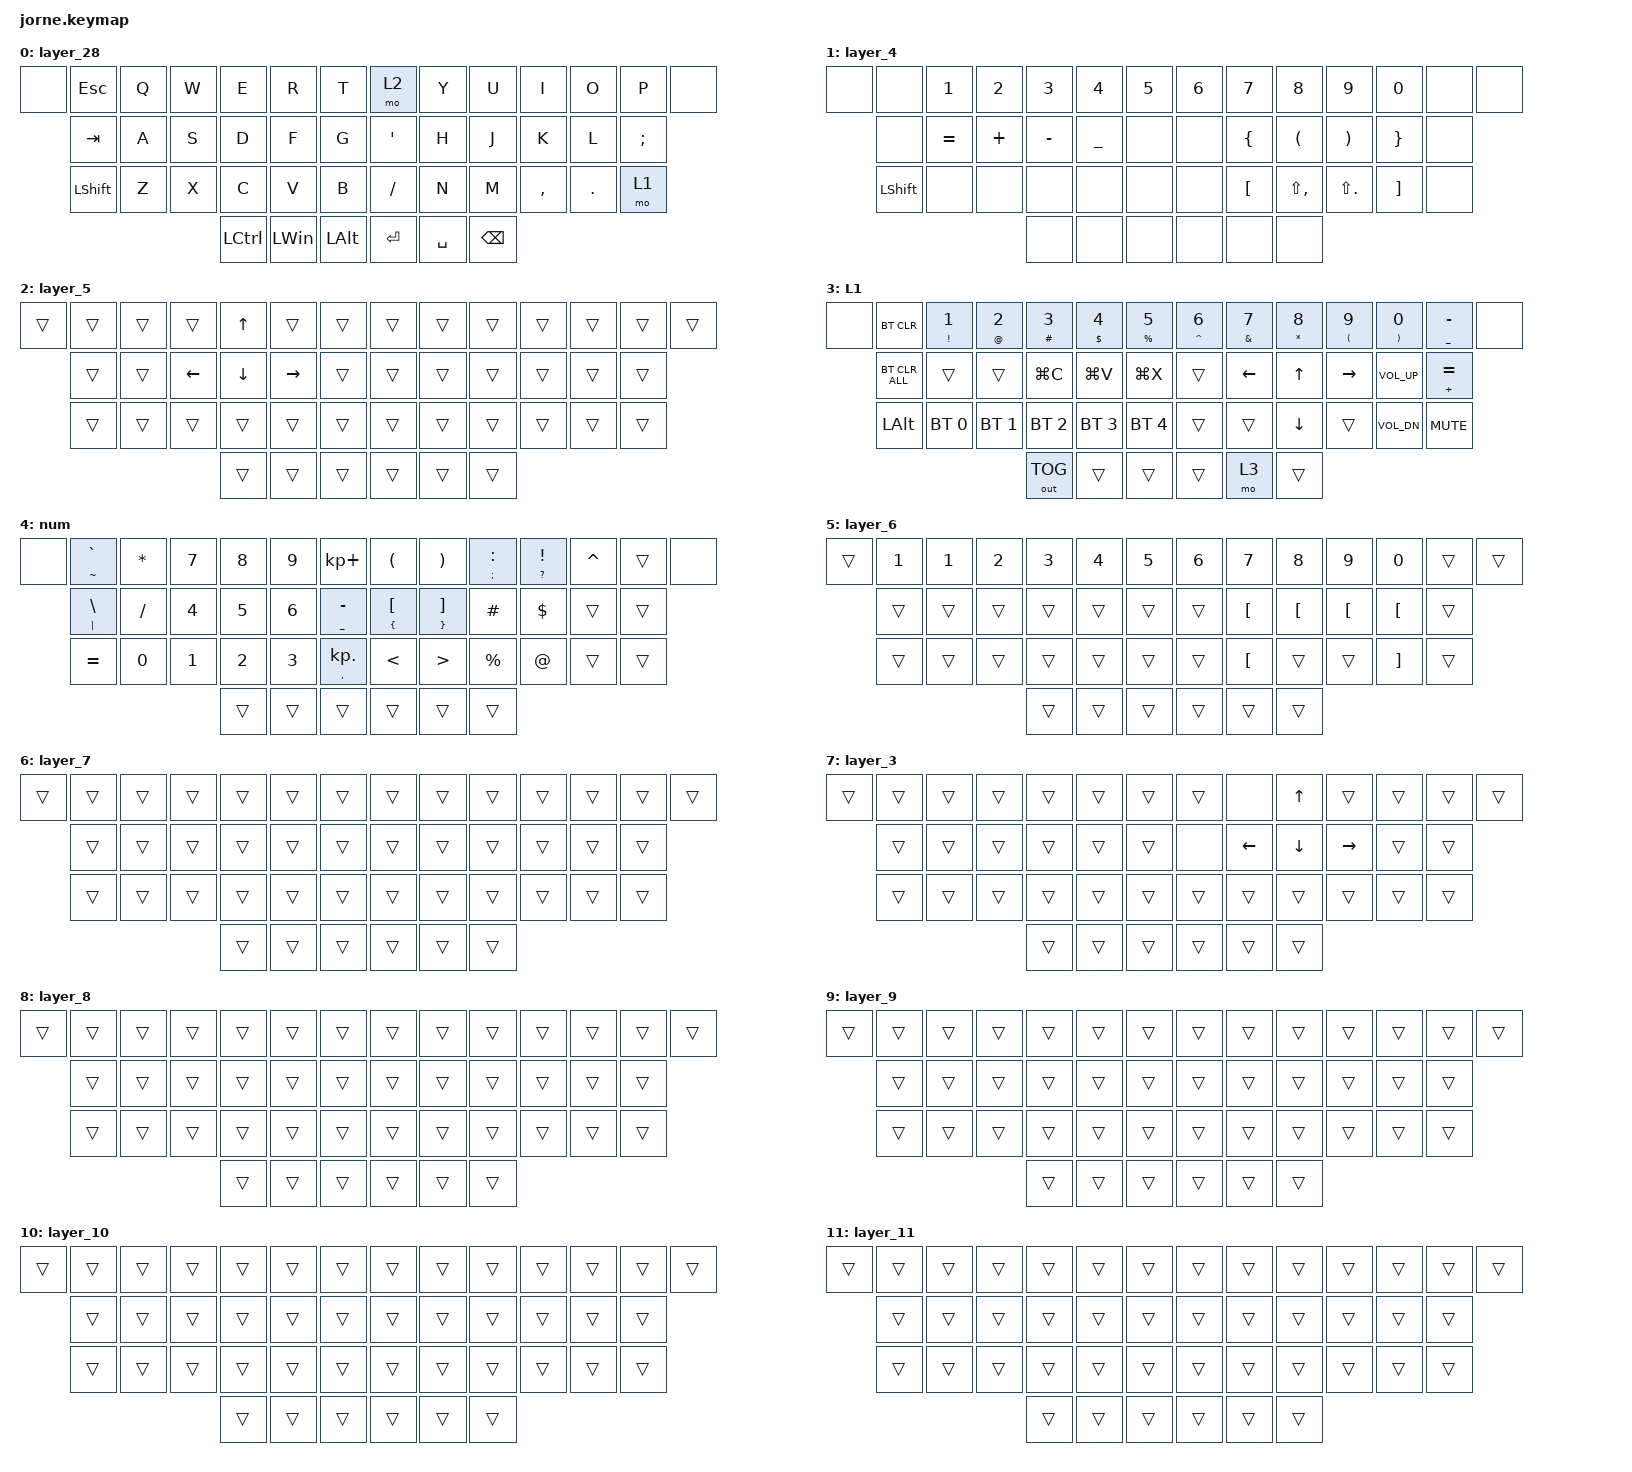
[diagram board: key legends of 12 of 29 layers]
/*
 * Copyright (c) 2020 The ZMK Contributors
 *
 * SPDX-License-Identifier: MIT
 */

#include <behaviors.dtsi>
#include <dt-bindings/zmk/bt.h>
#include <dt-bindings/zmk/keys.h>
#include <dt-bindings/zmk/outputs.h>

/ {
    combos {
        compatible = "zmk,combos";

        combo_game {
            bindings = <&tog 28>;
            key-positions = <38 43>;
            timeout-ms = <200>;
        };
    };

    behaviors {
        hml: hml {
            compatible = "zmk,behavior-hold-tap";
            label = "HML";
            bindings = <&kp>, <&kp>;

            #binding-cells = <2>;
            tapping-term-ms = <220>;
            quick-tap-ms = <175>;
            flavor = "balanced";
            require-prior-idle-ms = <100>;
            hold-trigger-key-positions = <7 8 9 10 11 12 13 20 21 22 23 24 25 32 33 34 35 36 37 38 39 40 41 42 43>;
            hold-trigger-on-release;
        };

        hmr: hmr {
            compatible = "zmk,behavior-hold-tap";
            label = "HMR";
            bindings = <&kp>, <&kp>;

            #binding-cells = <2>;
            tapping-term-ms = <220>;
            quick-tap-ms = <175>;
            require-prior-idle-ms = <100>;
            flavor = "balanced";
            hold-trigger-key-positions = <0 1 2 3 4 5 6 14 15 16 17 18 19 26 27 28 29 30 31 38 39 40 41 42 43>;
            hold-trigger-on-release;
        };

        tkl: tkl {
            compatible = "zmk,behavior-hold-tap";
            label = "TKL";
            bindings = <&mo>, <&kp>;

            #binding-cells = <2>;
            tapping-term-ms = <220>;
            quick-tap-ms = <175>;
            flavor = "balanced";
            require-prior-idle-ms = <100>;
            hold-trigger-key-positions = <7 8 9 10 11 12 13 20 21 22 23 24 25 32 33 34 35 36 37 38 39 40 41 42 43>;
            hold-trigger-on-release;
        };

        tkr: tkr {
            compatible = "zmk,behavior-hold-tap";
            label = "TKR";
            bindings = <&mo>, <&kp>;

            #binding-cells = <2>;
            tapping-term-ms = <220>;
            quick-tap-ms = <175>;
            require-prior-idle-ms = <100>;
            flavor = "balanced";
            hold-trigger-key-positions = <0 1 2 3 4 5 6 14 15 16 17 18 19 26 27 28 29 30 31 38 39 40 41 42 43>;
            hold-trigger-on-release;
        };
    };

    keymap {
        compatible = "zmk,keymap";

        layer_28 {
            bindings = <
&none  &kp ESC     &kp Q  &kp W  &kp E      &kp R     &kp T           &mo 2      &kp Y      &kp U          &kp I      &kp O    &kp P          &none
       &kp TAB     &kp A  &kp S  &kp D      &kp F     &kp G           &kp APOS   &kp H      &kp J          &kp K      &kp L    &kp SEMICOLON
       &kp LSHIFT  &kp Z  &kp X  &kp C      &kp V     &kp B           &kp SLASH  &kp N      &kp M          &kp COMMA  &kp DOT  &mo 1
                                 &kp LCTRL  &kp LWIN  &kp LEFT_ALT    &kp ENTER  &kp SPACE  &kp BACKSPACE
            >;
        };

        layer_4 {
            bindings = <
&none  &none           &kp NUMBER_1  &kp NUMBER_2  &kp NUMBER_3  &kp NUMBER_4    &kp NUMBER_5    &kp NUMBER_6  &kp NUMBER_7    &kp NUMBER_8          &kp NUMBER_9           &kp NUMBER_0     &none  &none
       &none           &kp EQUAL     &kp PLUS      &kp MINUS     &kp UNDERSCORE  &none           &none         &kp LEFT_BRACE  &kp LEFT_PARENTHESIS  &kp RIGHT_PARENTHESIS  &kp RIGHT_BRACE  &none
       &kp LEFT_SHIFT  &none         &none         &none         &none           &none           &none         &kp LBKT        &kp LS(COMMA)         &kp LS(DOT)            &kp RBKT         &none
                                                   &none         &none           &none           &none         &none           &none
            >;
        };

        layer_5 {
            bindings = <
&trans  &trans  &trans  &trans          &kp UP_ARROW    &trans     &trans    &trans  &trans  &trans  &trans  &trans  &trans  &trans
        &trans  &trans  &kp LEFT_ARROW  &kp DOWN_ARROW  &kp RIGHT  &trans    &trans  &trans  &trans  &trans  &trans  &trans
        &trans  &trans  &trans          &trans          &trans     &trans    &trans  &trans  &trans  &trans  &trans  &trans
                                        &trans          &trans     &trans    &trans  &trans  &trans
            >;
        };

        L1 {
            bindings = <
&none  &bt BT_CLR      &mt EXCLAMATION NUMBER_1  &mt AT_SIGN NUMBER_2  &mt POUND NUMBER_3  &mt DOLLAR NUMBER_4  &mt PERCENT NUMBER_5    &mt CARET NUMBER_6  &mt AMPERSAND NUMBER_7  &mt ASTERISK NUMBER_8  &mt LEFT_PARENTHESIS NUMBER_9  &mt RIGHT_PARENTHESIS NUMBER_0  &mt UNDERSCORE MINUS  &none
       &bt BT_CLR_ALL  &trans                    &trans                &kp LG(C)           &kp LG(V)            &kp LG(X)               &trans              &kp LEFT_ARROW          &kp UP_ARROW           &kp RIGHT_ARROW                &kp C_VOLUME_UP                 &mt PLUS EQUAL
       &kp LEFT_ALT    &bt BT_SEL 0              &bt BT_SEL 1          &bt BT_SEL 2        &bt BT_SEL 3         &bt BT_SEL 4            &trans              &trans                  &kp DOWN_ARROW         &trans                         &kp C_VOL_DN                    &kp K_MUTE
                                                                       &out OUT_TOG        &trans               &trans                  &trans              &mo 3                   &trans
            >;
        };

        num {
            bindings = <
&none  &mt TILDE GRAVE  &kp ASTERISK  &kp N7  &kp N8  &kp N9  &kp KP_PLUS             &kp LEFT_PARENTHESIS         &kp RIGHT_PARENTHESIS          &mt SEMICOLON COLON  &mt QUESTION EXCLAMATION  &kp CARET  &trans  &none
       &mt PIPE BSLH    &kp SLASH     &kp N4  &kp N5  &kp N6  &mt UNDERSCORE MINUS    &mt LEFT_BRACE LEFT_BRACKET  &mt RIGHT_BRACE RIGHT_BRACKET  &kp HASH             &kp DOLLAR                &trans     &trans
       &kp EQUAL        &kp NUMBER_0  &kp N1  &kp N2  &kp N3  &mt COMMA KP_DOT        &kp LESS_THAN                &kp GREATER_THAN               &kp PERCENT          &kp AT_SIGN               &trans     &trans
                                              &trans  &trans  &trans                  &trans                       &trans                         &trans
            >;
        };

        layer_6 {
            bindings = <
&trans  &kp N1  &kp N1  &kp N2  &kp N3  &kp N4  &kp N5    &kp N6  &kp N7    &kp N8    &kp N9    &kp N0    &trans  &trans
        &trans  &trans  &trans  &trans  &trans  &trans    &trans  &kp LBKT  &kp LBKT  &kp LBKT  &kp LBKT  &trans
        &trans  &trans  &trans  &trans  &trans  &trans    &trans  &kp LBKT  &trans    &trans    &kp RBKT  &trans
                                &trans  &trans  &trans    &trans  &trans    &trans
            >;
        };

        layer_7 {
            bindings = <
&trans  &trans  &trans  &trans  &trans  &trans  &trans    &trans  &trans  &trans  &trans  &trans  &trans  &trans
        &trans  &trans  &trans  &trans  &trans  &trans    &trans  &trans  &trans  &trans  &trans  &trans
        &trans  &trans  &trans  &trans  &trans  &trans    &trans  &trans  &trans  &trans  &trans  &trans
                                &trans  &trans  &trans    &trans  &trans  &trans
            >;
        };

        layer_3 {
            bindings = <
&trans  &trans  &trans  &trans  &trans  &trans  &trans    &trans  &none     &kp UP_ARROW    &trans     &trans  &trans  &trans
        &trans  &trans  &trans  &trans  &trans  &trans    &none   &kp LEFT  &kp DOWN_ARROW  &kp RIGHT  &trans  &trans
        &trans  &trans  &trans  &trans  &trans  &trans    &trans  &trans    &trans          &trans     &trans  &trans
                                &trans  &trans  &trans    &trans  &trans    &trans
            >;
        };

        layer_8 {
            bindings = <
&trans  &trans  &trans  &trans  &trans  &trans  &trans    &trans  &trans  &trans  &trans  &trans  &trans  &trans
        &trans  &trans  &trans  &trans  &trans  &trans    &trans  &trans  &trans  &trans  &trans  &trans
        &trans  &trans  &trans  &trans  &trans  &trans    &trans  &trans  &trans  &trans  &trans  &trans
                                &trans  &trans  &trans    &trans  &trans  &trans
            >;
        };

        layer_9 {
            bindings = <
&trans  &trans  &trans  &trans  &trans  &trans  &trans    &trans  &trans  &trans  &trans  &trans  &trans  &trans
        &trans  &trans  &trans  &trans  &trans  &trans    &trans  &trans  &trans  &trans  &trans  &trans
        &trans  &trans  &trans  &trans  &trans  &trans    &trans  &trans  &trans  &trans  &trans  &trans
                                &trans  &trans  &trans    &trans  &trans  &trans
            >;
        };

        layer_10 {
            bindings = <
&trans  &trans  &trans  &trans  &trans  &trans  &trans    &trans  &trans  &trans  &trans  &trans  &trans  &trans
        &trans  &trans  &trans  &trans  &trans  &trans    &trans  &trans  &trans  &trans  &trans  &trans
        &trans  &trans  &trans  &trans  &trans  &trans    &trans  &trans  &trans  &trans  &trans  &trans
                                &trans  &trans  &trans    &trans  &trans  &trans
            >;
        };

        layer_11 {
            bindings = <
&trans  &trans  &trans  &trans  &trans  &trans  &trans    &trans  &trans  &trans  &trans  &trans  &trans  &trans
        &trans  &trans  &trans  &trans  &trans  &trans    &trans  &trans  &trans  &trans  &trans  &trans
        &trans  &trans  &trans  &trans  &trans  &trans    &trans  &trans  &trans  &trans  &trans  &trans
                                &trans  &trans  &trans    &trans  &trans  &trans
            >;
        };

        layer_12 {
            bindings = <
&trans  &trans  &trans  &trans  &trans  &trans  &trans    &trans  &trans  &trans  &trans  &trans  &trans  &trans
        &trans  &trans  &trans  &trans  &trans  &trans    &trans  &trans  &trans  &trans  &trans  &trans
        &trans  &trans  &trans  &trans  &trans  &trans    &trans  &trans  &trans  &trans  &trans  &trans
                                &trans  &trans  &trans    &trans  &trans  &trans
            >;
        };

        layer_13 {
            bindings = <
&trans  &trans  &trans  &trans  &trans  &trans  &trans    &trans  &trans  &trans  &trans  &trans  &trans  &trans
        &trans  &trans  &trans  &trans  &trans  &trans    &trans  &trans  &trans  &trans  &trans  &trans
        &trans  &trans  &trans  &trans  &trans  &trans    &trans  &trans  &trans  &trans  &trans  &trans
                                &trans  &trans  &trans    &trans  &trans  &trans
            >;
        };

        layer_14 {
            bindings = <
&trans  &trans  &trans  &trans  &trans  &trans  &trans    &trans  &trans  &trans  &trans  &trans  &trans  &trans
        &trans  &trans  &trans  &trans  &trans  &trans    &trans  &trans  &trans  &trans  &trans  &trans
        &trans  &trans  &trans  &trans  &trans  &trans    &trans  &trans  &trans  &trans  &trans  &trans
                                &trans  &trans  &trans    &trans  &trans  &trans
            >;
        };

        layer_15 {
            bindings = <
&trans  &trans  &trans  &trans  &trans  &trans  &trans    &trans  &trans  &trans  &trans  &trans  &trans  &trans
        &trans  &trans  &trans  &trans  &trans  &trans    &trans  &trans  &trans  &trans  &trans  &trans
        &trans  &trans  &trans  &trans  &trans  &trans    &trans  &trans  &trans  &trans  &trans  &trans
                                &trans  &trans  &trans    &trans  &trans  &trans
            >;
        };

        layer_16 {
            bindings = <
&trans  &trans  &trans  &trans  &trans  &trans  &trans    &trans  &trans  &trans  &trans  &trans  &trans  &trans
        &trans  &trans  &trans  &trans  &trans  &trans    &trans  &trans  &trans  &trans  &trans  &trans
        &trans  &trans  &trans  &trans  &trans  &trans    &trans  &trans  &trans  &trans  &trans  &trans
                                &trans  &trans  &trans    &trans  &trans  &trans
            >;
        };

        layer_17 {
            bindings = <
&trans  &trans  &trans  &trans  &trans  &trans  &trans    &trans  &trans  &trans  &trans  &trans  &trans  &trans
        &trans  &trans  &trans  &trans  &trans  &trans    &trans  &trans  &trans  &trans  &trans  &trans
        &trans  &trans  &trans  &trans  &trans  &trans    &trans  &trans  &trans  &trans  &trans  &trans
                                &trans  &trans  &trans    &trans  &trans  &trans
            >;
        };

        layer_18 {
            bindings = <
&trans  &trans  &trans  &trans  &trans  &trans  &trans    &trans  &trans  &trans  &trans  &trans  &trans  &trans
        &trans  &trans  &trans  &trans  &trans  &trans    &trans  &trans  &trans  &trans  &trans  &trans
        &trans  &trans  &trans  &trans  &trans  &trans    &trans  &trans  &trans  &trans  &trans  &trans
                                &trans  &trans  &trans    &trans  &trans  &trans
            >;
        };

        layer_19 {
            bindings = <
&trans  &trans  &trans  &trans  &trans  &trans  &trans    &trans  &trans  &trans  &trans  &trans  &trans  &trans
        &trans  &trans  &trans  &trans  &trans  &trans    &trans  &trans  &trans  &trans  &trans  &trans
        &trans  &trans  &trans  &trans  &trans  &trans    &trans  &trans  &trans  &trans  &trans  &trans
                                &trans  &trans  &trans    &trans  &trans  &trans
            >;
        };

        layer_20 {
            bindings = <
&trans  &trans  &trans  &trans  &trans  &trans  &trans    &trans  &trans  &trans  &trans  &trans  &trans  &trans
        &trans  &trans  &trans  &trans  &trans  &trans    &trans  &trans  &trans  &trans  &trans  &trans
        &trans  &trans  &trans  &trans  &trans  &trans    &trans  &trans  &trans  &trans  &trans  &trans
                                &trans  &trans  &trans    &trans  &trans  &trans
            >;
        };

        layer_21 {
            bindings = <
&trans  &trans  &trans  &trans  &trans  &trans  &trans    &trans  &trans  &trans  &trans  &trans  &trans  &trans
        &trans  &trans  &trans  &trans  &trans  &trans    &trans  &trans  &trans  &trans  &trans  &trans
        &trans  &trans  &trans  &trans  &trans  &trans    &trans  &trans  &trans  &trans  &trans  &trans
                                &trans  &trans  &trans    &trans  &trans  &trans
            >;
        };

        layer_22 {
            bindings = <
&trans  &trans  &trans  &trans  &trans  &trans  &trans    &trans  &trans  &trans  &trans  &trans  &trans  &trans
        &trans  &trans  &trans  &trans  &trans  &trans    &trans  &trans  &trans  &trans  &trans  &trans
        &trans  &trans  &trans  &trans  &trans  &trans    &trans  &trans  &trans  &trans  &trans  &trans
                                &trans  &trans  &trans    &trans  &trans  &trans
            >;
        };

        layer_23 {
            bindings = <
&trans  &trans  &trans  &trans  &trans  &trans  &trans    &trans  &trans  &trans  &trans  &trans  &trans  &trans
        &trans  &trans  &trans  &trans  &trans  &trans    &trans  &trans  &trans  &trans  &trans  &trans
        &trans  &trans  &trans  &trans  &trans  &trans    &trans  &trans  &trans  &trans  &trans  &trans
                                &trans  &trans  &trans    &trans  &trans  &trans
            >;
        };

        layer_24 {
            bindings = <
&trans  &trans  &trans  &trans  &trans  &trans  &trans    &trans  &trans  &trans  &trans  &trans  &trans  &trans
        &trans  &trans  &trans  &trans  &trans  &trans    &trans  &trans  &trans  &trans  &trans  &trans
        &trans  &trans  &trans  &trans  &trans  &trans    &trans  &trans  &trans  &trans  &trans  &trans
                                &trans  &trans  &trans    &trans  &trans  &trans
            >;
        };

        layer_25 {
            bindings = <
&trans  &trans  &trans  &trans  &trans  &trans  &trans    &trans  &trans  &trans  &trans  &trans  &trans  &trans
        &trans  &trans  &trans  &trans  &trans  &trans    &trans  &trans  &trans  &trans  &trans  &trans
        &trans  &trans  &trans  &trans  &trans  &trans    &trans  &trans  &trans  &trans  &trans  &trans
                                &trans  &trans  &trans    &trans  &trans  &trans
            >;
        };

        layer_26 {
            bindings = <
&trans  &trans  &trans  &trans  &trans  &trans  &trans    &trans  &trans  &trans  &trans  &trans  &trans  &trans
        &trans  &trans  &trans  &trans  &trans  &trans    &trans  &trans  &trans  &trans  &trans  &trans
        &trans  &trans  &trans  &trans  &trans  &trans    &trans  &trans  &trans  &trans  &trans  &trans
                                &trans  &trans  &trans    &trans  &trans  &trans
            >;
        };

        layer_27 {
            bindings = <
&trans  &trans  &trans  &trans  &trans  &trans  &trans    &trans  &trans  &trans  &trans  &trans  &trans  &trans
        &trans  &trans  &trans  &trans  &trans  &trans    &trans  &trans  &trans  &trans  &trans  &trans
        &trans  &trans  &trans  &trans  &trans  &trans    &trans  &trans  &trans  &trans  &trans  &trans
                                &trans  &trans  &trans    &trans  &trans  &trans
            >;
        };

        base {
            // Jorne: 44 keys (positions 0 and 13 are extra outer keys, not present physically)
            // -----------------------------------------------------------------------------------------
            // | x |  ESC |  Q  |  W  |  E  |  R  |  T  |   |  Y  |  U   |  I  |  O  |  P  | BKSP | x |
            //     | TAB  |  A  |  S  |  D  |  F  |  G  |   |  H  |  J   |  K  |  L  |  '  |  '   |
            //     | SHFT |  Z  |  X  |  C  |  V  |  B  |   |  N  |  M   |  ,  |  .  |  /  | SHFT |
            //                        | GUI | LWR | SPC |   | ENT | RSE  | ALT |

            bindings = <
&none  &kp ESC     &kp Q  &kp W  &kp E      &kp R     &kp T           &kp Y      &kp U  &kp I      &kp O    &kp P          &kp BACKSPACE  &none
       &kp TAB     &kp A  &kp S  &kp D      &kp F     &kp G           &kp H      &kp J  &kp K      &kp L    &kp SEMICOLON  &kp ENTER
       &kp LSHIFT  &kp Z  &kp X  &kp C      &kp V     &kp B           &kp N      &kp M  &kp COMMA  &kp DOT  &kp FSLH       &mo 4
                                 &kp LCTRL  &kp LWIN  &kp LEFT_ALT    &kp SPACE  &mo 1  &mo 3
            >;
        };
    };

    conditional_layers { compatible = "zmk,conditional-layers"; };
};
